# K1921VK028 register map
Vendor: NIIET; Series: K1921VKx; File version: 2.17
CPU: CM4 r0p1, little endian, MPU, FPU, 4 interrupt priority bits
Registers are 32-bit, read-write, reset 0x0 unless marked. A register's access mark holds for its fields unless they carry their own. Offsets are from the block's base; [hi:lo] are bit positions; {n}, {i} and the like mark numbered series.

## SIU — System integration unit registers
Base 0x40080000
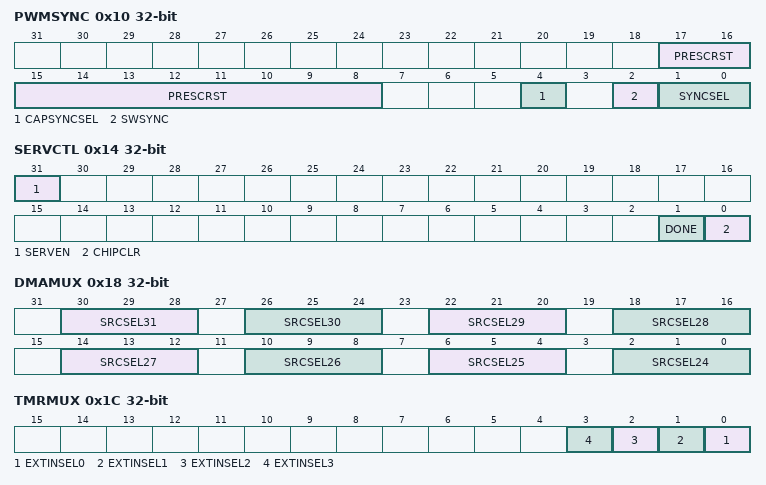
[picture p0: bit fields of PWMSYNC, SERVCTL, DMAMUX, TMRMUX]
0x10 PWMSYNC — PWM syncronization control register
  [17:8] PRESCRST — PWM prescalers reset control
  [4] CAPSYNCSEL — CAP sync scheme control
  [2] SWSYNC — SYNCI pulse software emulation on PWM0
  [1:0] SYNCSEL — PWM sync scheme control
0x14 SERVCTL — Service mode control register
  [31] SERVEN ro — Service mode enable status
  [1] DONE ro — Status of clear task
  [0] CHIPCLR — On-chip memories full clear task start
0x18 DMAMUX — DMA external requests mux control register
  [30:28] SRCSEL31 — Request source select for DMA channel 31
    0=GPIOH (request by GPIOH); 1=ETMR3 (request by ETMR3); 2=PWM6B (request by PWM6B); 3=PWM7B (request by PWM7B); 4=GPIOL (request by GPIOL); 5=GPIOM (request by GPIOM)
  [26:24] SRCSEL30 — Request source select for DMA channel 30
    0=GPIOG (request by GPIOG); 1=ETMR2 (request by ETMR2); 2=PWM4B (request by PWM4B); 3=PWM5B (request by PWM5B); 4=QEP3 (request by QEP3); 5=SDFM3 (request by SDFM3)
  [22:20] SRCSEL29 — Request source select for DMA channel 29
    0=GPIOF (request by GPIOF); 1=ETMR1 (request by ETMR1); 2=PWM2B (request by PWM2B); 3=PWM3B (request by PWM3B); 4=QEP2 (request by QEP2); 5=SDFM2 (request by SDFM2)
  [18:16] SRCSEL28 — Request source select for DMA channel 28
    0=GPIOE (request by GPIOE); 1=ETMR0 (request by ETMR0); 2=PWM0B (request by PWM0B); 3=PWM1B (request by PWM1B); 4=PWM8B (request by PWM8B); 5=PWM9B (request by PWM9B)
  [14:12] SRCSEL27 — Request source select for DMA channel 27
    0=GPIOD (request by GPIOD); 1=TMR3 (request by TMR3); 2=PWM6A (request by PWM6A); 3=PWM7A (request by PWM7A); 4=GPIOJ (request by GPIOJ); 5=GPIOK (request by GPIOK)
  [10:8] SRCSEL26 — Request source select for DMA channel 26
    0=GPIOC (request by GPIOC); 1=TMR2 (request by TMR2); 2=PWM4A (request by PWM4A); 3=PWM5A (request by PWM5A); 4=QEP1 (request by QEP1); 5=SDFM1 (request by SDFM1)
  [6:4] SRCSEL25 — Request source select for DMA channel 25
    0=GPIOB (request by GPIOB); 1=TMR1 (request by TMR1); 2=PWM2A (request by PWM2A); 3=PWM3A (request by PWM3A); 4=QEP0 (request by QEP0); 5=SDFM0 (request by SDFM0)
  [2:0] SRCSEL24 — Request source select for DMA channel 24
    0=GPIOA (request by GPIOA); 1=TMR0 (request by TMR0); 2=PWM0A (request by PWM0A); 3=PWM1A (request by PWM1A); 4=PWM8A (request by PWM8A); 5=PWM9A (request by PWM9A)
0x1C TMRMUX — TMR external clock mux control register
  [all] fields
    0=IO (use external input IO TMRx_IN); 1=RTC1K (use 1kHz RTC signal)
  [n] EXTINSEL{n} (n=0..3) — Select external input source for TMR{n}
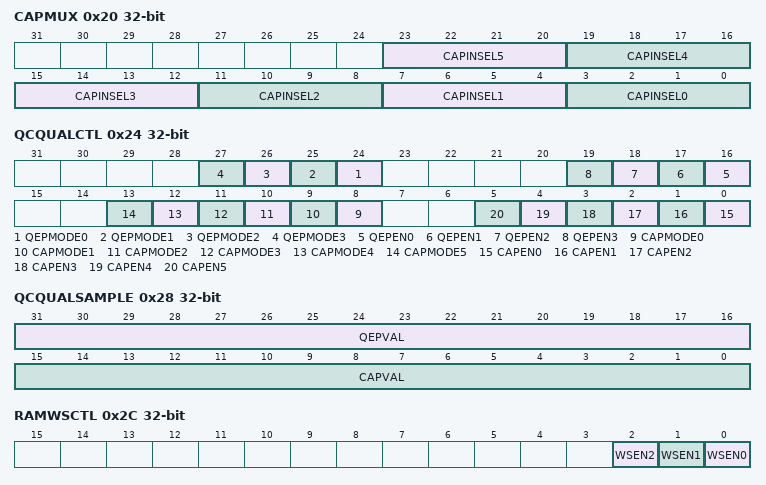
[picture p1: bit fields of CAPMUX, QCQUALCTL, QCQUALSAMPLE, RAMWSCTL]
0x20 CAPMUX — CAP input mux control register
  [23:20] CAPINSEL5 — Select input source for CAP5
    0=CAP5 (default CAP5 input); {v}=SDFMCHZ{v-8} (SDFM comparator {v-8} HZ output) (v=8..11); {v}=QEPI{v-12} (QEP{v-12} I input) (v=12..15)
  [19:16] CAPINSEL4 — Select input source for CAP4
    0=CAP4 (default CAP4 input); {v}=SDFMCHZ{v-8} (SDFM comparator {v-8} HZ output) (v=8..11); {v}=QEPB{v-12} (QEP{v-12} B input) (v=12..15)
  [15:12] CAPINSEL3 — Select input source for CAP3
    0=CAP3 (default CAP3 input); {v}=SDFMCHZ{v-8} (SDFM comparator {v-8} HZ output) (v=8..11); {v}=QEPA{v-12} (QEP{v-12} A input) (v=12..15)
  [11:8] CAPINSEL2 — Select input source for CAP2
    0=CAP2 (default CAP2 input); {v}=SDFMCHZ{v-8} (SDFM comparator {v-8} HZ output) (v=8..11); {v}=QEPI{v-12} (QEP{v-12} I input) (v=12..15)
  [7:4] CAPINSEL1 — Select input source for CAP1
    0=CAP1 (default CAP1 input); {v}=SDFMCHZ{v-8} (SDFM comparator {v-8} HZ output) (v=8..11); {v}=QEPB{v-12} (QEP{v-12} B input) (v=12..15)
  [3:0] CAPINSEL0 — Select input source for CAP0
    0=CAP0 (default CAP0 input); {v}=SDFMCHZ{v-8} (SDFM comparator {v-8} HZ output) (v=8..11); {v}=QEPA{v-12} (QEP{v-12} A input) (v=12..15)
0x24 QCQUALCTL — QEP and ECAP qualifier control register
  [n+24] QEPMODE{n} (n=0..3) — Select mode of qualifier for QEP{n}
  [n+16] QEPEN{n} (n=0..3) — Enable qualifier for QEP{n}
  [n+8] CAPMODE{n} (n=0..5) — Select mode of qualifier for CAP{n}
  [n] CAPEN{n} (n=0..5) — Enable qualifier for CAP{n}
0x28 QCQUALSAMPLE — QEP and CAP qualifier sample period set register
  [31:16] QEPVAL — Set sample period of qualifer for all QEPs
  [15:0] CAPVAL — Set sample period of qualifer for all CAPs
0x2C RAMWSCTL — RAM waitstates control register
  [2] WSEN2 — RAM2 additional waitstate
  [1] WSEN1 — RAM1 additional waitstate
  [0] WSEN0 — RAM0 additional waitstate
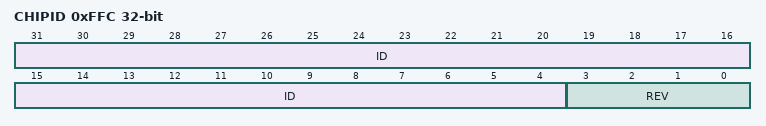
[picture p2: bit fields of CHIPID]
0xFFC CHIPID ro — Chip identifier
  [31:4] ID — Model ID
  [3:0] REV — Revision number
